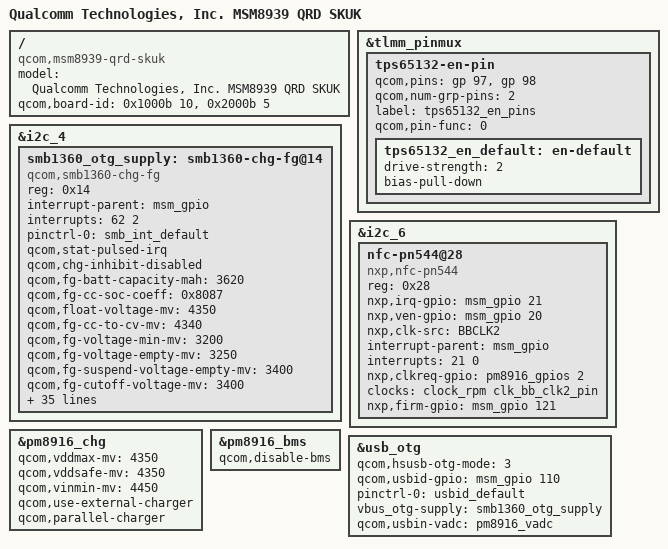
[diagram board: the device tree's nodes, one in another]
/* Copyright (c) 2014, The Linux Foundation. All rights reserved.
 *
 * This program is free software; you can redistribute it and/or modify
 * it under the terms of the GNU General Public License version 2 and
 * only version 2 as published by the Free Software Foundation.
 *
 * This program is distributed in the hope that it will be useful,
 * but WITHOUT ANY WARRANTY; without even the implied warranty of
 * MERCHANTABILITY or FITNESS FOR A PARTICULAR PURPOSE.  See the
 * GNU General Public License for more details.
 */

/dts-v1/;

#include "./namek-msm8939-qrd-skuk/namek-msm8939.dtsi"
#include "./namek-msm8939-qrd-skuk/namek-msm8939-qrd-skuk.dtsi"
#include "./namek-msm8939-qrd-skuk/namek-dsi-panel-goworld-1080p-cmd.dtsi"
#include "./namek-msm8939-qrd-skuk/namek-dsi-panel-eR63422-truly-1080p-cmd.dtsi"
#include "./namek-msm8939-qrd-skuk/namek-msm8939-camera-sensor-qrd.dtsi"

/ {
	model = "Qualcomm Technologies, Inc. MSM8939 QRD SKUK";
	compatible = "qcom,msm8939-qrd-skuk", "qcom,msm8939-qrd", "qcom,msm8939", "qcom,qrd";
	qcom,board-id = <0x1000b 10>, <0x2000b 5>;
};

&tlmm_pinmux {
	tps65132-en-pin {
		qcom,pins = <&gp 97>, <&gp 98>;
		qcom,num-grp-pins = <2>;
		label = "tps65132_en_pins";
		qcom,pin-func = <0>;

		tps65132_en_default: en-default {
			drive-strength = <2>;
			bias-pull-down;
		};
	};
};

&i2c_4 {
	smb1360_otg_supply: smb1360-chg-fg@14 {
		compatible = "qcom,smb1360-chg-fg";
		reg = <0x14>;
		interrupt-parent = <&msm_gpio>;
		interrupts = <62 2>;
		pinctrl-names = "default";
		pinctrl-0 = <&smb_int_default>;
		qcom,stat-pulsed-irq;
		qcom,chg-inhibit-disabled;
		/*battery capacity*/
		qcom,fg-batt-capacity-mah = <3620>;
		qcom,fg-cc-soc-coeff = <0x8087>;
		qcom,float-voltage-mv = <4350>;
		qcom,fg-cc-to-cv-mv = <4340>;
		qcom,fg-voltage-min-mv = <3200>;
		qcom,fg-voltage-empty-mv = <3250>;
		qcom,fg-suspend-voltage-empty-mv = <3400>;
		qcom,fg-cutoff-voltage-mv = <3400>;
		qcom,fg-auto-recharge-soc = <99>;
		qcom,fg-delta-soc = <1>;
		qcom,thermistor-c1-coeff = <0x86C2>;
		qcom,iterm-ma = <100>;
		//qcom,recharge-thresh-mv = <100>;
		qcom,charging-timeout = <1536>;
		qcom,otg-batt-curr-limit = <1500>;
		qcom,thermal-mitigation = <1200 700 600 0>;
		regulator-name = "smb1360_otg_vreg";
		qcom,fg-reset-at-pon;
		qcom,rsense-10mhom;
		qcom,fg-reset-thresold-mv = <250>;
		qcom,parallel-charging-enabled;
		qcom,max-parallel-current-ma = <450>;

		qcom,batt-id-disabled;
		/*battery-profile selection properties */
		qcom,batt-profile-select;
		qcom,smb1360-vadc = <&pm8916_vadc>;
		qcom,batt-id-vref-uv = <1800000>;
		qcom,batt-id-rpullup-kohm = <100>;
		qcom,profile-a-rid-kohm = <33>;
		qcom,profile-b-rid-kohm = <91>;
		qcom,shdn-after-pwroff;
		qcom,config-hard-thresholds;
		qcom,soft-jeita-supported;
		qcom,hot-bat-decidegc = <600>;
		qcom,cold-bat-decidegc = <(-50)>;
		qcom,warm-bat-decidegc = <450>;
		qcom,cool-bat-decidegc = <0>;
		qcom,warm-bat-mv = <4200>;
		qcom,cool-bat-mv = <4200>;
		qcom,warm-bat-ma = <450>;
		qcom,cool-bat-ma = <450>;
        qcom,cool-recharge-decidegc = <50>;
        qcom,warm-recharge-decidegc = <400>;
		qcom,cool-warm-disable-charging;
		qcom,hot-bat-mv = <4200>;
	};
};

&i2c_6 {
    nfc-pn544@28 {
        compatible = "nxp,nfc-pn544";
        reg = <0x28>;
        nxp,irq-gpio = <&msm_gpio 21 0x00>;
        nxp,ven-gpio = <&msm_gpio 20 0x00>;
        nxp,clk-src = "BBCLK2";
        interrupt-parent = <&msm_gpio>;
        interrupts = <21 0>;
        interrupt-names = "nfc_irq";
        nxp,clkreq-gpio = <&pm8916_gpios 2 0>;
        clocks = <&clock_rpm clk_bb_clk2_pin>;
        clock-names = "ref_clk";
        nxp,firm-gpio = <&msm_gpio 121 0x00>;
    };
};

&pm8916_chg {
	status = "ok";
	qcom,vddmax-mv = <4350>;
	qcom,vddsafe-mv = <4350>;
	qcom,vinmin-mv = <4450>;  //NAMEK-2384
	qcom,use-external-charger;
	qcom,parallel-charger;
};

&pm8916_bms {
	status = "ok";
	qcom,disable-bms;
};


&usb_otg {
       qcom,hsusb-otg-mode = <3>;
       qcom,usbid-gpio = <&msm_gpio 110 0>;
       pinctrl-names = "default";
       pinctrl-0 = <&usbid_default>;
       vbus_otg-supply = <&smb1360_otg_supply>;
	   qcom,usbin-vadc = <&pm8916_vadc>;
};

